# i2c register map
Vendor: Texas Instruments
Peripheral module from a debugger description file (folder tm4e1231h6zrb).
Registers are 32-bit, read-write, no defined reset value unless marked. A register's access mark holds for its fields unless they carry their own. Offsets are as the file gives them; lines under a group give offsets from that group; [hi:lo] are bit positions; {n}, {i} and the like mark numbered series; 'fields as' and 'values as' point back to an identical list; <NAME> marks a mode.

## I2C0 — I2C register offsets
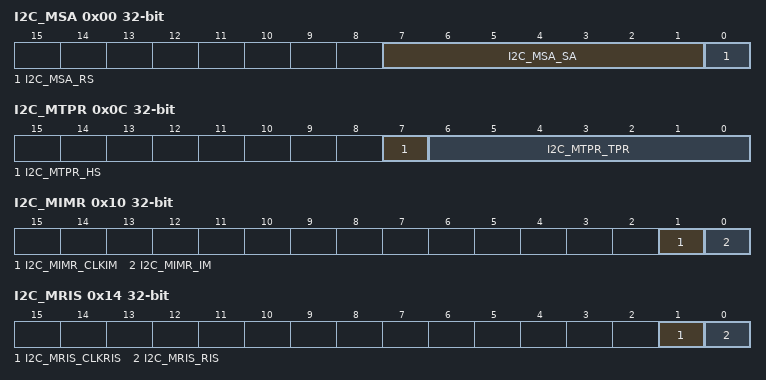
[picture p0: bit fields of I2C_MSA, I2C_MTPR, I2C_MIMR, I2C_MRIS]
0x00 I2C_MSA — I2C Master Slave Address
  [7:1] I2C_MSA_SA — I2C Slave Address
  [0] I2C_MSA_RS — Receive not send
0x04 I2C_MCS — I2C Master Control/Status
  [7] I2C_MCS_CLKTO — Clock Timeout Error
  [6] I2C_MCS_BUSBSY — Bus Busy
  [5] I2C_MCS_IDLE — I2C Idle
  [5] I2C_MCS_QCMD — Quick Command
  [4] I2C_MCS_ARBLST — Arbitration Lost
  [4] I2C_MCS_HS — High-Speed Enable
  [3] I2C_MCS_ACK — Data Acknowledge Enable
  [3] I2C_MCS_DATACK — Acknowledge Data
  [2] I2C_MCS_ADRACK — Acknowledge Address
  [2] I2C_MCS_STOP — Generate STOP
  [1] I2C_MCS_ERROR — Error
  [1] I2C_MCS_START — Generate START
  [0] I2C_MCS_RUN — I2C Master Enable
  [0] I2C_MCS_BUSY — I2C Busy
0x08 I2C_MDR — I2C Master Data
  [7:0] I2C_MDR_DATA — This byte contains the data transferred during a transaction
0x0C I2C_MTPR — I2C Master Timer Period
  [7] I2C_MTPR_HS — High-Speed Enable
  [6:0] I2C_MTPR_TPR — Timer Period
0x10 I2C_MIMR — I2C Master Interrupt Mask
  [1] I2C_MIMR_CLKIM — Clock Timeout Interrupt Mask
  [0] I2C_MIMR_IM — Master Interrupt Mask
0x14 I2C_MRIS ro — I2C Master Raw Interrupt Status
  [1] I2C_MRIS_CLKRIS — Clock Timeout Raw Interrupt Status
  [0] I2C_MRIS_RIS — Master Raw Interrupt Status
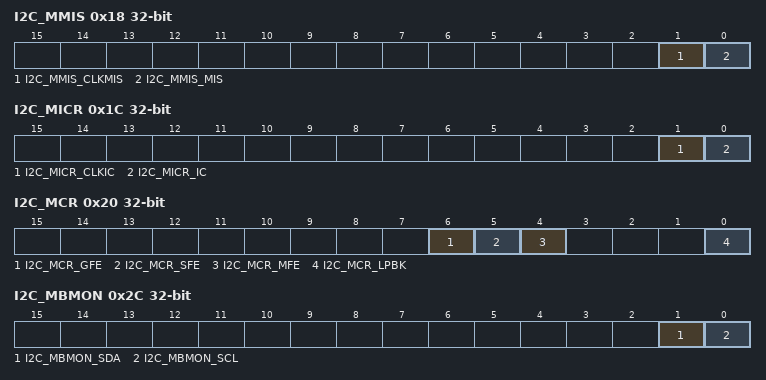
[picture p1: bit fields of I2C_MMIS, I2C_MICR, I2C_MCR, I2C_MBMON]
0x18 I2C_MMIS ro — I2C Master Masked Interrupt Status
  [1] I2C_MMIS_CLKMIS — Clock Timeout Masked Interrupt Status
  [0] I2C_MMIS_MIS — Masked Interrupt Status
0x1C I2C_MICR wo — I2C Master Interrupt Clear
  [1] I2C_MICR_CLKIC — Clock Timeout Interrupt Clear
  [0] I2C_MICR_IC — Master Interrupt Clear
0x20 I2C_MCR — I2C Master Configuration
  [6] I2C_MCR_GFE — I2C Glitch Filter Enable
  [5] I2C_MCR_SFE — I2C Slave Function Enable
  [4] I2C_MCR_MFE — I2C Master Function Enable
  [0] I2C_MCR_LPBK — I2C Loopback
0x24 I2C_MCLKOCNT — I2C Master Clock Low Timeout Count
  [7:0] I2C_MCLKOCNT_CNTL — I2C Master Count
0x2C I2C_MBMON ro — I2C Master Bus Monitor
  [1] I2C_MBMON_SDA — I2C SDA Status
  [0] I2C_MBMON_SCL — I2C SCL Status
0x38 I2C_MCR2 — I2C Master Configuration 2
  [6:4] I2C_MCR2_GFPW — I2C Glitch Filter Pulse Width
    0=I2C_MCR2_GFPW_BYPASS (Bypass); 1=1 clock; 2=2 clocks; 3=3 clocks; 4=4 clocks; 5=8 clocks; 6=16 clocks; 7=31 clocks
0x800 I2C_SOAR — I2C Slave Own Address
  [6:0] I2C_SOAR_OAR
0x804 I2C_SCSR ro — I2C Slave Control/Status
  [5] I2C_SCSR_QCMDRW — Quick Command Read / Write
  [4] I2C_SCSR_QCMDST — Quick Command Status
  [3] I2C_SCSR_OAR2SEL — OAR2 Address Matched
  [2] I2C_SCSR_FBR — First Byte Received
  [1] I2C_SCSR_TREQ — Transmit Request
  [0] I2C_SCSR_DA — Device Active
  [0] I2C_SCSR_RREQ — Receive Request
0x808 I2C_SDR — I2C Slave Data
  [7:0] I2C_SDR_DATA — Data for Transfer
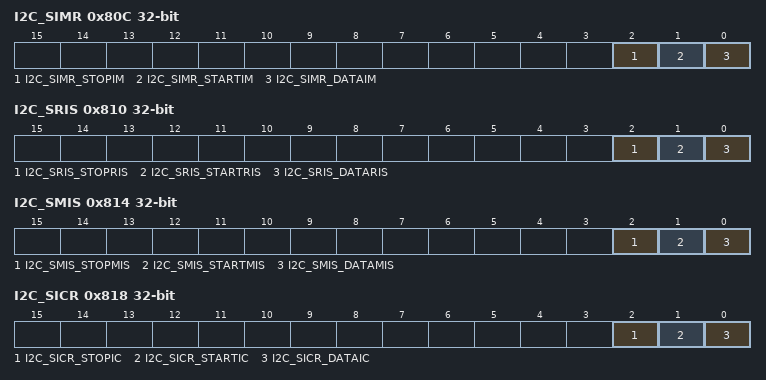
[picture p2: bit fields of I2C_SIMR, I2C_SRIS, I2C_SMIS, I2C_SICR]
0x80C I2C_SIMR — I2C Slave Interrupt Mask
  [2] I2C_SIMR_STOPIM — Stop Condition Interrupt Mask
  [1] I2C_SIMR_STARTIM — Start Condition Interrupt Mask
  [0] I2C_SIMR_DATAIM — Data Interrupt Mask
0x810 I2C_SRIS ro — I2C Slave Raw Interrupt Status
  [2] I2C_SRIS_STOPRIS — Stop Condition Raw Interrupt Status
  [1] I2C_SRIS_STARTRIS — Start Condition Raw Interrupt Status
  [0] I2C_SRIS_DATARIS — Data Raw Interrupt Status
0x814 I2C_SMIS ro — I2C Slave Masked Interrupt Status
  [2] I2C_SMIS_STOPMIS — Stop Condition Masked Interrupt Status
  [1] I2C_SMIS_STARTMIS — Start Condition Masked Interrupt Status
  [0] I2C_SMIS_DATAMIS — Data Masked Interrupt Status
0x818 I2C_SICR wo — I2C Slave Interrupt Clear
  [2] I2C_SICR_STOPIC — Stop Condition Interrupt Clear
  [1] I2C_SICR_STARTIC — Start Condition Interrupt Clear
  [0] I2C_SICR_DATAIC — Data Interrupt Clear
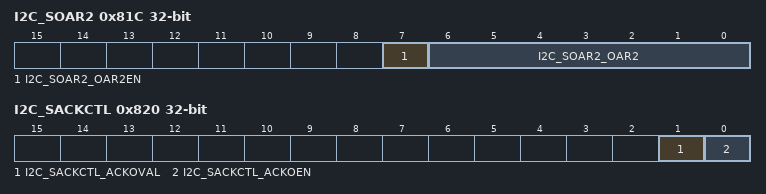
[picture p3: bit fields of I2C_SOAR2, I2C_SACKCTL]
0x81C I2C_SOAR2 — I2C Slave Own Address 2
  [7] I2C_SOAR2_OAR2EN — I2C Slave Own Address 2 Enable
  [6:0] I2C_SOAR2_OAR2 — I2C Slave Own Address 2
0x820 I2C_SACKCTL — I2C Slave ACK Control
  [1] I2C_SACKCTL_ACKOVAL — I2C Slave ACK Override Value
  [0] I2C_SACKCTL_ACKOEN — I2C Slave ACK Override Enable
0xFC0 I2C_PP ro — I2C Peripheral Properties
  [0] I2C_PP_HS — High-Speed Capable
0xFC4 I2C_PC ro — I2C Peripheral Configuration
  [0] I2C_PC_HS — High-Speed Capable
